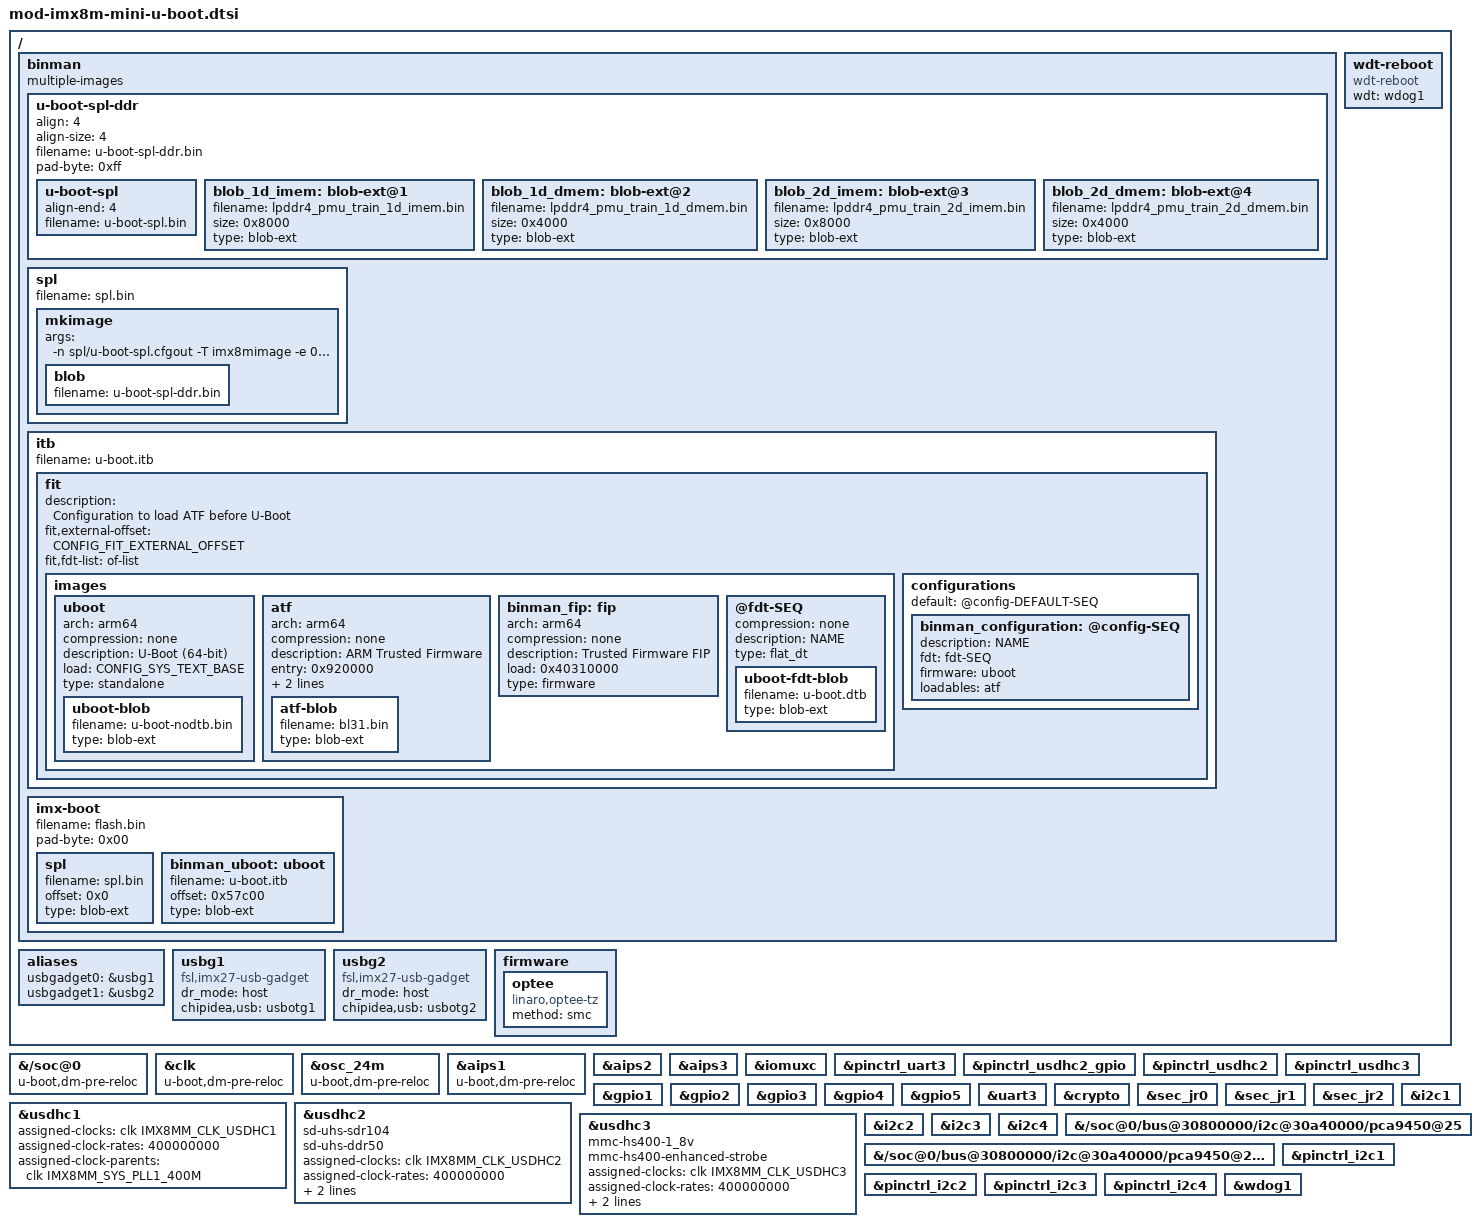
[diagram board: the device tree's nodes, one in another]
// SPDX-License-Identifier: GPL-2.0+
/*
 * Copyright 2019 NXP
 */

/ {
    binman: binman {
        multiple-images;
    };

	wdt-reboot {
		compatible = "wdt-reboot";
		wdt = <&wdog1>;
		u-boot,dm-spl;
	};

    aliases {
      usbgadget0 = &usbg1;
      usbgadget1 = &usbg2;
    };

    usbg1: usbg1 {
      compatible = "fsl,imx27-usb-gadget";
      dr_mode = "host";
      chipidea,usb = <&usbotg1>;
      status = "okay";
    };

    usbg2: usbg2 {
      compatible = "fsl,imx27-usb-gadget";
      dr_mode = "host";
      chipidea,usb = <&usbotg2>;
      status = "okay";
    };

	firmware {
		optee {
			compatible = "linaro,optee-tz";
			method = "smc";
		};
	};
};

&{/soc@0} {
	u-boot,dm-pre-reloc;
	u-boot,dm-spl;
};

&clk {
	u-boot,dm-spl;
	u-boot,dm-pre-reloc;
	/delete-property/ assigned-clocks;
	/delete-property/ assigned-clock-parents;
	/delete-property/ assigned-clock-rates;
};

&osc_24m {
	u-boot,dm-spl;
	u-boot,dm-pre-reloc;
};

&aips1 {
	u-boot,dm-spl;
	u-boot,dm-pre-reloc;
};

&aips2 {
	u-boot,dm-spl;
};

&aips3 {
	u-boot,dm-spl;
};

&iomuxc {
	u-boot,dm-spl;
};

&pinctrl_uart3 {
	u-boot,dm-spl;
};

&pinctrl_usdhc2_gpio {
	u-boot,dm-spl;
};

&pinctrl_usdhc2 {
	u-boot,dm-spl;
};

&pinctrl_usdhc3 {
	u-boot,dm-spl;
};

&gpio1 {
	u-boot,dm-spl;
};

&gpio2 {
	u-boot,dm-spl;
};

&gpio3 {
	u-boot,dm-spl;
};

&gpio4 {
	u-boot,dm-spl;
};

&gpio5 {
	u-boot,dm-spl;
};

&uart3 {
	u-boot,dm-spl;
};

&crypto {
	u-boot,dm-spl;
};

&sec_jr0 {
	u-boot,dm-spl;
};

&sec_jr1 {
	u-boot,dm-spl;
};

&sec_jr2 {
	u-boot,dm-spl;
};

&usdhc1 {
	u-boot,dm-spl;
	assigned-clocks = <&clk IMX8MM_CLK_USDHC1>;
	assigned-clock-rates = <400000000>;
	assigned-clock-parents = <&clk IMX8MM_SYS_PLL1_400M>;
};

&usdhc2 {
	u-boot,dm-spl;
	sd-uhs-sdr104;
	sd-uhs-ddr50;
	assigned-clocks = <&clk IMX8MM_CLK_USDHC2>;
	assigned-clock-rates = <400000000>;
	assigned-clock-parents = <&clk IMX8MM_SYS_PLL1_400M>;
};

&usdhc3 {
	u-boot,dm-spl;
	mmc-hs400-1_8v;
	mmc-hs400-enhanced-strobe;
	assigned-clocks = <&clk IMX8MM_CLK_USDHC3>;
	assigned-clock-rates = <400000000>;
	assigned-clock-parents = <&clk IMX8MM_SYS_PLL1_400M>;
};

&i2c1 {
	u-boot,dm-spl;
};

&i2c2 {
	u-boot,dm-spl;
};

&i2c3 {
	u-boot,dm-spl;
};

&i2c4 {
	u-boot,dm-spl;
};

&{/soc@0/bus@30800000/i2c@30a40000/pca9450@25} {
	u-boot,dm-spl;
};

&{/soc@0/bus@30800000/i2c@30a40000/pca9450@25/regulators} {
	u-boot,dm-spl;
};

&pinctrl_i2c1 {
	u-boot,dm-spl;
};

&pinctrl_i2c2 {
	u-boot,dm-spl;
};

&pinctrl_i2c3 {
	u-boot,dm-spl;
};

&pinctrl_i2c4 {
	u-boot,dm-spl;
};

&wdog1 {
	u-boot,dm-spl;
};

&binman {
	u-boot-spl-ddr {
		align = <4>;
		align-size = <4>;
		filename = "u-boot-spl-ddr.bin";
		pad-byte = <0xff>;

		u-boot-spl {
			align-end = <4>;
			filename = "u-boot-spl.bin";
		};

		blob_1d_imem: blob-ext@1 {
			filename = "lpddr4_pmu_train_1d_imem.bin";
			size = <0x8000>;
			type = "blob-ext";
		};

		blob_1d_dmem: blob-ext@2 {
			filename = "lpddr4_pmu_train_1d_dmem.bin";
			size = <0x4000>;
			type = "blob-ext";
		};

		blob_2d_imem: blob-ext@3 {
			filename = "lpddr4_pmu_train_2d_imem.bin";
			size = <0x8000>;
			type = "blob-ext";
		};

		blob_2d_dmem: blob-ext@4 {
			filename = "lpddr4_pmu_train_2d_dmem.bin";
			size = <0x4000>;
			type = "blob-ext";
		};
	};

	spl {
		filename = "spl.bin";

		mkimage {
			args = "-n spl/u-boot-spl.cfgout -T imx8mimage -e 0x7e1000";

			blob {
				filename = "u-boot-spl-ddr.bin";
			};
		};
	};

	itb {
		filename = "u-boot.itb";

		fit {
			description = "Configuration to load ATF before U-Boot";
			fit,external-offset = <CONFIG_FIT_EXTERNAL_OFFSET>;
			fit,fdt-list = "of-list";
			#address-cells = <1>;

			images {
				uboot {
					arch = "arm64";
					compression = "none";
					description = "U-Boot (64-bit)";
					load = <CONFIG_SYS_TEXT_BASE>;
					type = "standalone";

					uboot-blob {
						filename = "u-boot-nodtb.bin";
						type = "blob-ext";
					};
				};

				atf {
					arch = "arm64";
					compression = "none";
					description = "ARM Trusted Firmware";
					entry = <0x920000>;
					load = <0x920000>;
					type = "firmware";

					atf-blob {
						filename = "bl31.bin";
						type = "blob-ext";
					};
				};

				binman_fip: fip {
					arch = "arm64";
					compression = "none";
					description = "Trusted Firmware FIP";
					load = <0x40310000>;
					type = "firmware";
				};

				@fdt-SEQ {
					compression = "none";
					description = "NAME";
					type = "flat_dt";

					uboot-fdt-blob {
						filename = "u-boot.dtb";
						type = "blob-ext";
					};
				};
			};

			configurations {
				default = "@config-DEFAULT-SEQ";

				binman_configuration: @config-SEQ {
					description = "NAME";
					fdt = "fdt-SEQ";
					firmware = "uboot";
					loadables = "atf";
				};
			};
		};
	};

	imx-boot {
		filename = "flash.bin";
		pad-byte = <0x00>;

		spl {
			filename = "spl.bin";
			offset = <0x0>;
			type = "blob-ext";
		};

		binman_uboot: uboot {
			filename = "u-boot.itb";
			offset = <0x57c00>;
			type = "blob-ext";
		};
	};
};
